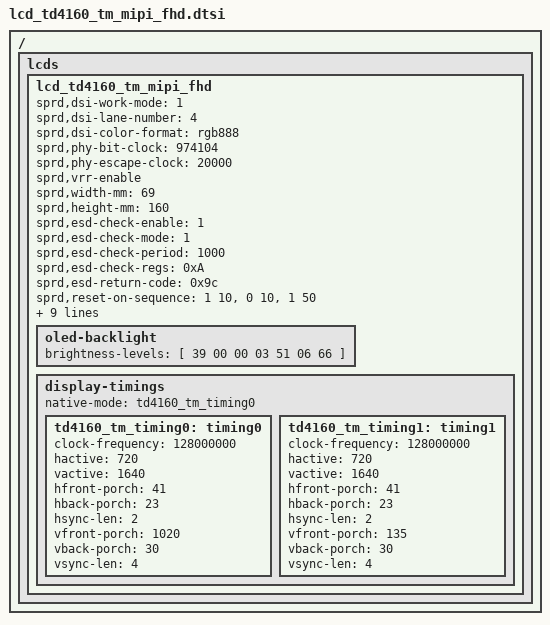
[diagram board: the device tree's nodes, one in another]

/*
 * td4160 TM LCD config dtsi file for spreadtrum
 *
 * Copyright (C) 2022, Spreadtrum Communications Inc.
 *
 * SPDX-License-Identifier: (GPL-2.0+ OR MIT)
 */

/ {
	fragment {
		target-path = "/";
		__overlay__ {
			lcds {
				lcd_td4160_tm_mipi_fhd: lcd_td4160_tm_mipi_fhd {

					sprd,dsi-work-mode = <1>; /* video burst mode*/
					sprd,dsi-lane-number = <4>;
					sprd,dsi-color-format = "rgb888";

					sprd,phy-bit-clock = <974104>;	/* kbps */
					sprd,phy-escape-clock = <20000>;/* kHz */
					sprd,vrr-enable;  /*60hz 90hz*/
					//sprd,power-gpio-delay = <20>; ms
					sprd,width-mm = <69>;
					sprd,height-mm = <160>;
					//sprd,dpi-clk-div = <6>;
					//sprd,video-lp-cmd-enable = <1>;
					//sprd,hporch-lp-disable = <1>;
					sprd,esd-check-enable = <1>;
					sprd,esd-check-mode = <1>;
					sprd,esd-check-period = <1000>;
					sprd,esd-check-regs = <0xA>;
					sprd,esd-return-code = <0x9c>;

					sprd,reset-on-sequence = <1 10>, <0 10>, <1 50>;
					sprd,reset-off-sequence = <0 5>;

					sprd,initial-command = [
						23 B0 00
                        23 B0 03
                        29 F0 CE 15 05 F0
                        29 00 00 04 F0 C1 01 81 
                        29 00 00 04 F0 CE 11 01 
                        29 00 00 04 F0 CE 12 46 
                        29 00 00 04 F0 CE 11 00 
                        29 00 00 04 F0 CE 12 B2 
                        23 00 00 02 B0 00 
                        29 00 00 04 F0 C0 06 0E 
                        29 00 00 04 F0 EB 00 07 
                        29 00 00 04 F0 EB 01 50 
                        29 00 00 04 F0 EB 06 00 
                        29 00 00 04 F0 ED 08 69
                        29 00 00 04 F0 ED 09 97 
                        29 00 00 04 F0 ED 0A 0E 
                        23 00 00 02 B0 03 
                        23 00 00 02 35 00 
                        23 00 00 02 B0 00 
                        29 00 00 07 B6 30 6A 00 86 C3 03 
                        23 00 00 03 51 00 00 
                        23 00
						];

					sprd,sleep-in-command = [
						13 14 00 01 28
                        13 78 00 01 10
						];

					sprd,sleep-out-command = [
						13 78 00 01 11
                        13 14 00 01 29
						];

					sprd,cabc-on-command = [
						23 00 00 02 55 03
						];

					sprd,cabc-off-command = [
						23 00 00 02 55 00
						];

					oled-backlight {
						//default-brightness = <900>;
						//sprd,max-level = <4095>;
						brightness-levels = [
						39 00 00 03 51 06 66
						];
					};

					display-timings {
						native-mode = <&td4160_tm_timing0>;

						td4160_tm_timing0: timing0 {
							clock-frequency = <128000000>;
							hactive = <720>;
							vactive = <1640>;
							hfront-porch = <41>;
							hback-porch = <23>;
							hsync-len = <2>;
							vfront-porch = <1020>;
							vback-porch = <30>;
							vsync-len = <4>;
						};
						td4160_tm_timing1: timing1 {
							clock-frequency = <128000000>;
							hactive = <720>;
							vactive = <1640>;
							hfront-porch = <41>;
							hback-porch = <23>;
							hsync-len = <2>;
							vfront-porch = <135>;
							vback-porch = <30>;
							vsync-len = <4>;
						};
					};
				};
			};
		};
	};
};
